# cslr_osd_001 register map
Vendor: Texas Instruments
Peripheral module from a debugger description file.
Registers are 32-bit, access per field, reset 0x0 unless marked. A register's access mark holds for its fields unless they carry their own. Offsets are as the file gives them; lines under a group give offsets from that group; [hi:lo] are bit positions; {n}, {i} and the like mark numbered series; 'fields as' and 'values as' point back to an identical list; <NAME> marks a mode.

## OSD — VPBE On Screen Display Subsystem (spec version: 1.00.w.02a)
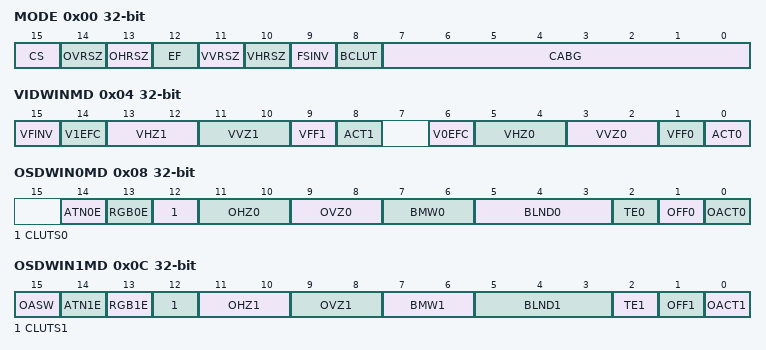
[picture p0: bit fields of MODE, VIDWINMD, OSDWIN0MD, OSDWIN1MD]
0x00 MODE — OSD mode register
  [15] CS rw — Cb/Cr or Cr/Cb format This bit selects the order of the input data relative to the placement of the Cb and Cr components
    0=CB_CR; 1=CR_CB
  [14] OVRSZ rw — OSD Window Vertical Expansion Enable When enabled, the bitmap window images are stretched by a factor of 6/5 in the vertical direction. Results in proper vertical sizing to display a normal VGA (640x480) image on a PAL television (720x576); i.e., 480 x 6/5=576
    0=X1; 1=X6_5
  [13] OHRSZ rw — OSD Window Horizontal Expansion Enable When enabled, the bitmap window images are stretched by a factor of 9/8 in the horizontal direction. Results in proper horizontal sizing to display a normal VGA (640x480) image on a PAL / NTSC television (720);
    0=X1; 1=X9_8
  [12] EF rw — Expansion Filter Enable Valid when either VVRSZ or VHRSZ is on, or video window smoothing is set. Caution is required when using the filter since expansion filter memory can only correspond to 720 horizontal pixels. *This bit is latched by VD.
    0=OFF; 1=ON
  [11] VVRSZ rw — Video Window Vertical Expansion Enable When enabled, the video window images are stretched by a factor of 6/5 in the vertical direction. Results in proper vertical sizing to display a normal VGA (640x480) image on a PAL television (720x576); i.e., 480 x 6/5=576 *This bit is latched by VD.
    0=X1; 1=X6_5
  [10] VHRSZ rw — Video Window Horizontal Expansion Enable When enabled, the video window images are stretched by a factor of 9/8 in the horizontal direction. Results in proper horizontal sizing to display a normal VGA (640x480) image on an NTSC/PAL television (720x???); i.e., 640 x 9/8 = 720 *This bit is latched by VD.
    0=X1; 1=X9_8
  [9] FSINV rw — Field signal inversion *This bit is latched by VD.
    0=UNINVERTED; 1=INVERTED
  [8] BCLUT rw — Background CLUT selection Selects look-up table for background color display *This bit is latched by VD.
    0=ROM; 1=RAM
  [7:0] CABG rw — Background Color CLUT Specifies the image display background color by CLUT address. In parts that do not display the image, color specified by this register is displayed.
0x04 VIDWINMD access not given — Video Window Mode Setup
  [15] VFINV rw — Video Window 0/1 Expansion filter coefficient Inverse Note: When V1EFC or V0EFC is set, this bit is valid
    0=NORMAL; 1=INVERSED
  [14] V1EFC rw — Video Window 1 Expansion filter coefficient Note: When VVRSZ and EF are set to 1, this bit is valid
    0=SAME4BOTH (same coefficients for field-0 and field-1); 1=DIFFERENT (different coefficients for field-0 and field-1)
  [13:12] VHZ1 rw — Video Window 0 horizontal direction zoom *This bit is latched by VD.
    0=X1; 1=X2; 2=X4
  [11:10] VVZ1 rw — Video Window 0 vertical direction zoom *This bit is latched by VD.
    0=X1; 1=X2; 2=X4
  [9] VFF1 rw — Video Window 0 display mode In Field mode, only the number of lines in a field, as specified in VIDWIN1YL, will be read from display memory and the data is repeated for each field sent to the VENC module. In Frame mode, 2x the number of lines in a field, as specified in VIDWIN1YL, will be read from display memory, with the data being interleaved for each field sent to the VENC module. This provides full vertical resolution of 2x VIDWIN1YL. *This bit is latched by VD.
    0=FIELDMODE; 1=FRAMEMODE
  [8] ACT1 rw — Sets image display on/off Video Window 0 *This bit is latched by VD.
    0=OFF; 1=ON
  [6] V0EFC rw — Video window 0 Expansion filter coefficient Note: When VVRSZ and EF are set to 1, this bit is valid
    values as V1EFC
  [5:4] VHZ0 rw — Video Window 0 horizontal direction zoom *This bit is latched by VD.
    0=X1; 1=X2; 2=X4
  [3:2] VVZ0 rw — Video Window 0 vertical direction zoom *This bit is latched by VD.
    0=X1; 1=X2; 2=X4
  [1] VFF0 rw — Video Window 0 display mode In Field mode, only the number of lines in a field, as specified in VIDWIN0YL, will be read from display memory and the data is repeated for each field sent to the VENC module. In Frame mode, 2x the number of lines in a field, as specified in VIDWIN0YL, will be read from display memory, with the data being interleaved for each field sent to the VENC module. This provides full vertical resolution of 2x VIDWIN0YL. *This bit is latched by VD.
    0=FIELDMODE; 1=FRAMEMODE
  [0] ACT0 rw — Sets image display on/off Video Window 0 *This bit is latched by VD.
    0=OFF; 1=ON
0x08 OSDWIN0MD — OSD Window 0 Mode Setup
  [14] ATN0E rw — Attenuation Enable for REC601
    0=NORMAL (Normal levels (Y 0-255, Cr 0-255, Cb 0-255)); 1=ATTENUATED (Attenuated levels (Y 16-235, Cr 16-240, Cb 16-240))
  [13] RGB0E rw — RGB input for window 0 Enable Note: When RGB0E bit in OSDWIN0MD register is set/enabled, RGB1E should not be set to 1 (parallel use is not allowed). The following equation is used to calculate YcbCr when RGB0E is set to 1. Y = 0.2990*R + 0.5870*G + 0.1140*B Cb = -0.1687*R - 0.3313*G + 0.5000*B + Offset(128) Cr = 0.5000*R - 0.4187*G - 0.0813*B + Offset(128)
    0=BMPLUT_MODE (bitmap input); 1=RGB16_MODE (16-bit RGB mode)
  [12] CLUTS0 rw — CLUT select for OSD Window 0 Selects look-up table that is used for OSD Window0 *This bit is latched by VD.
    0=ROM_LUT (ROM-look-up table); 1=RAM_LUT (RAM-look-up table)
  [11:10] OHZ0 rw — OSD Window0 Horizontal Zoom *This bit is latched by VD.
    0=X1; 1=X2; 2=X4
  [9:8] OVZ0 rw — OSD Window0 Vertical Zoom *This bit is latched by VD.
    0=X1; 1=X2; 2=X4
  [7:6] BMW0 rw — Bitmap bit width for OSD window 0 *This bit is latched by VD. Note: This is valid only for bitmap type, and when the OSD window is in RGB input mode, bit width is automatically set to 16-bit and this register setting is ignored
    0=1_BIT; 1=2_BITS; 2=4_BITS; 3=8_BITS
  [5:3] BLND0 rw — Blending Ratio for OSD Window 0 Sets blending ratio of OSD Window 0 and Video Window 0 *This bit is latched by VD.
    0=OSD0_VID1 (W0-0 V0-1); 1=OSD1_VID7 (W0-1/8 V0-7/8); 2=OSD2_VID6 (W0-2/8 V0-6/8); 3=OSD3_VID5 (W0-3/8 V0-5/8); 4=OSD4_VID4 (W0-4/8 V0-4/8); 5=OSD5_VID3 (W0-5/8 V0-3/8); 6=OSD6_VID2 (W0-6/8 V0-2/8); 7=OSD1_VID0 (W0-1 V0-0)
  [2] TE0 rw — Transparency Enable for OSD Window 0 When Transparency is disabled, the entire bitmap window is blended with the video windows according to BLND0. Bitmap Mode When Transparency is enabled, blending is only performed for pixels whose bitmap value is 0, according to BLND0. RGB Mode When Transparency is enabled and the pixel value is the same as TRANSPVAL, the YCbCr data converted from RGB value and video windows are blended according to the blending ratio specified in BLND0. *This bit is latched by VD.
    0=DISABLE; 1=ENABLE
  [1] OFF0 rw — OSD Window 0 Display Mode In Field mode, only the number of lines in a field, as specified in OSDWIN0YL, will be read from display memory and the data is repeated for each field sent to the VENC module. In Frame mode, 2x the number of lines in a field, as specified in OSDWIN0YL, will be read from display memory, with the data being interleaved for each field sent to the VENC module. This provides full vertical resolution of 2x OSDWIN0YL. *This bit is latched by VD.
    0=FIELDMODE; 1=FRAMEMODE
  [0] OACT0 rw — OSD Window 0 Active (displayed) *This bit is latched by VD.
    0=OFF; 1=ON
0x0C OSDWIN1MD — OSD Window 1 Mode Setup
  [15] OASW rw — OSD Window 1 Attribute Mode Enable This bit enables attribute mode for OSD WindoW0. *This bit is latched by VD.
    0=OSDWINDOW1 (OSD WindoW0); 1=ATTRIBUTEWINDOW
  [14] ATN1E rw — Attenuation Enable for REC601 OASW=0
    values as OSDWIN0MD.ATN0E
  [13] RGB1E rw — RGB input for window 1 Enable OASW=0 Note: When RGB0E bit in OSDWIN1MD register is set/enabled, RGB0E should not be set to 1 (parallel use is not allowed). The following equation is used to calculate YcbCr when RGB1E is set to 1. Y = 0.2990*R + 0.5870*G + 0.1140*B Cb = -0.1687*R - 0.3313*G + 0.5000*B + Offset(128) Cr = 0.5000*R - 0.4187*G - 0.0813*B + Offset(128)
    0=BMPLUT_MODE (bitmap input); 1=RGB16_MODE (16-bit RGB mode)
  [12] CLUTS1 rw — CLUT Select for OSD Window 1 OASW=0 Selects look-up table that is used for OSD WindoW 0
    0=ROM_LUT (ROM-look-up table); 1=RAM_LUT (RAM-look-up table)
  [11:10] OHZ1 rw — OSD WindoW 1 Horizontal Zoom OASW=0 *This bit is latched by VD.
    0=X1; 1=X2; 2=X4
  [9:8] OVZ1 rw — OSD WindoW 1 Vertical Zoom OASW=0 *This bit is latched by VD.
    0=X1; 1=X2; 2=X4
  [7:6] BMW1 rw — Bitmap Bit Width for OSD Window 1 OASW=0 Bitmap bit width for OSD WindoW0 *This bit is latched by VD.
    0=1_BIT; 1=2_BITS; 2=4_BITS; 3=8_BITS
  [5:3] BLND1 rw — Blending Ratio for OSD WindoW 1 OASW=0 Sets blending ratio of OSD window 1 and Video Window 0 *This bit is latched by VD.
    values as OSDWIN0MD.BLND0
  [2] TE1 rw — Transparency Enable for OSD Window 1 OASW=0 When Transparency is disabled, the entire bitmap window is blended with the video windows according to BLND1. Bitmap Mode When Transparency is enabled, blending is only performed for pixels whose bitmap value is 0, according to BLND1. RGB Mode When Transparency is enabled and the pixel value is the same as TRANSPVAL, the YCbCr data converted from RGB value and video windows are blended according to the blending ratio specified in BLND1. *This bit is latched by VD.
    0=DISABLE; 1=ENABLE
  [1] OFF1 rw — OSD Window 1 Display Mode OASW=0 In Field mode, only the number of lines in a field, as specified in OSDWIN1YL, will be read from display memory and the data is repeated for each field sent to the VENC module. In Frame mode, 2x the number of lines in a field, as specified in OSDWIN1YL, will be read from display memory, with the data being interleaved for each field sent to the VENC module. This provides full vertical resolution of 2x OSDWIN1YL. *This bit is latched by VD.
    0=FIELDMODE; 1=FRAMEMODE
  [0] OACT1 rw — OSD Window 1 Active (displayed) OASW=0 *This bit is latched by VD.
    0=OFF; 1=ON
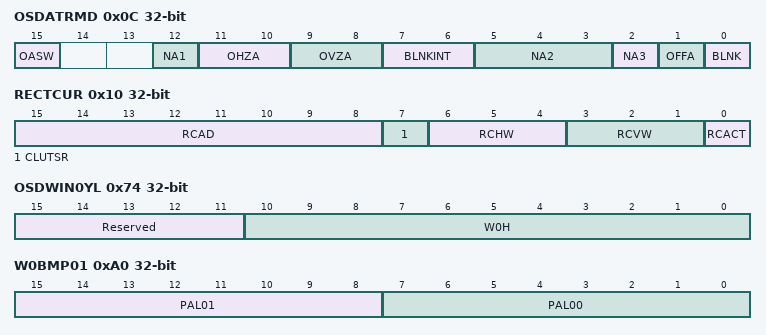
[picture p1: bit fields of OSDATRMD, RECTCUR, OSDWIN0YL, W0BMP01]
0x0C OSDATRMD access not given — OSD Attribute Window Mode Setup
  [15] OASW rw — OSD Window 1 Attribute Mode Enable This bit enables attribute mode for OSD WindoW0. *This bit is latched by VD.
    0=OSDWINDOW1 (OSD WindoW0); 1=ATTRIBUTEWINDOW
  [12] NA1 rw — Not Applicable in Attribute Window OASW=1 Not Used, Please set to 0 *This bit is latched by VD.
  [11:10] OHZA rw — OSD Attribute Window Horizontal Zoom OASW=1 *This bit is latched by VD.
    0=X1; 1=X2; 2=X4
  [9:8] OVZA rw — OSD WindoW0 or Attribute Window Vertical Zoom OASW=1 *This bit is latched by VD.
    0=X1; 1=X2; 2=X4
  [7:6] BLNKINT rw — Blinking Interval OASW=1 Specifies the blinking interval of the attribute window in units of 8 VD pulses *This bit is latched by VD.
    0=1_UNIT; 1=2_UNITS; 2=3_UNITS; 3=4_UNITS
  [5:3] NA2 rw — Not Applicable in Attribute Window OASW=1 Not Used, Please set to 0 *This bit is latched by VD.
  [2] NA3 rw — Not Applicable in Attribute Window OASW=1 Not Used, Please set to 0 *This bit is latched by VD.
  [1] OFFA rw — OSD Attribute Window Display Mode OASW=1 *This bit is latched by VD.
    0=FIELDMODE; 1=FRAMEMODE
  [0] BLNK rw — OSD Attribute Window Blink Enable OASW=1 *This bit is latched by VD.
    0=DISABLE; 1=ENABLE
0x10 RECTCUR — Rectangular Cursor Setup
  [15:8] RCAD rw — Rectangular Cursor Color Palette Address
  [7] CLUTSR rw — CLUT Select *This bit is latched by VD.
    0=ROM_LUT (ROM-look-up table); 1=RAM_LUT (RAM-look-up table)
  [6:4] RCHW rw — Rectangular Cursor Horizontal Line Width Width is 4xRCHW, with 0 interpreted as 1 pixel Range is: 1,4,8,16,20,24,28 pixels *This bit is latched by VD.
  [3:1] RCVW rw — Rectangular Cursor Vertical Line Width Width is 2xRCVW, with 0 interpreted as 1 line Range is: 1,2,4,6,8,10,12,14 lines *This bit is latched by VD.
  [0] RCACT rw — Rectangular Cursor Active (displayed) *This bit is latched by VD.
    0=OFF; 1=ON
0x14 RSV0 ro — Reserved
0x18 VIDWIN0OFST — Video Window 0 Offset
  [8:0] V0LO rw — Video Window 0 Line Offset Number of burst transfers (32-bytes) in a horizontal line. Video data format is YCbYCr, or 32-bits per 2 pixels, which gives 16-pixels/burst: Line width in pixels/16 e.g., 720/16 = 45 (0x2D) Note: If line width setting for the window result in a non-integer value, round the value up to the next larger integer and organize the data in SDRAM so that each line begins on a burst boundary. *This bit is latched by VD.
0x1C VIDWIN1OFST — Video Window 1 Offset
  [8:0] V1LO rw — Video Window 1 Line Offset Number of burst transfers (32-bytes) in a horizontal line. Video data format is YCbYCr, or 32-bits per 2 pixels, which gives 16-pixels/burst: Line width in pixels/16 e.g., 720/16 = 45 (0x2D) Note: If line width setting for the window result in a non-integer value, round the value up to the next larger integer and organize the data in SDRAM so that each line begins on a burst boundary. *This bit is latched by VD.
0x20 OSDWIN0OFST — OSD Window 0 Offset
  [8:0] O0LO rw — OSD Window 0 Line Offset Number of burst transfers (32-bytes) in a horizontal line. This depends on OSD window bit depth: Line width in pixels * bitdepth/256-bits/burst e.g., 64*8/256 = 2 Example: Offsets for 256 pixels horizontal: 1-bit mode : ((256x 1)/8)/32 = 1(0x0001) 2-bit mode : ((256x 2)/8)/32 = 2(0x0002) 4-bit mode : ((256x 4)/8)/32 = 4(0x0004) 8-bit mode : ((256x 8)/8)/32 = 8(0x0008) RGB565 mode : ((256x16)/8)/32 = 16(0x0010) Note: If line width and bitdepth settings for the window result in a non-integer value, round the value up to the next larger integer and organize the data in SDRAM so that each line begins on a burst boundary. *This bit is latched by VD.
0x24 OSDWIN1OFST — OSD Window 1 Offset
  [8:0] O1LO rw — OSD Window 1 Line Offset Number of burst transfers (32-bytes) in a horizontal line. This depends on OSD window bit depth: Line width in pixels * bitdepth/256-bits/burst e.g., 64*8/256 = 2 Example: Offsets for 256 pixels horizontal: 1-bit mode : ((256x 1)/8)/32 = 1(0x0001) 2-bit mode : ((256x 2)/8)/32 = 2(0x0002) 4-bit mode : ((256x 4)/8)/32 = 4(0x0004) 8-bit mode : ((256x 8)/8)/32 = 8(0x0008) RGB565 mode : ((256x16)/8)/32 = 16(0x0010) Note: If line width and bitdepth settings for the window result in a non-integer value, round the value up to the next larger integer and organize the data in SDRAM so that each line begins on a burst boundary. *This bit is latched by VD.
0x28 RSV1 ro — Reserved
0x2C VIDWIN0ADR ro — Video Window 0 Address
  [31:0] VIDWIN0ADR — Video Window 0 SDRAM Source Address The SDRAM source address is an absolute byte address. Note that the address should be aligned on a 32-byte (burst) boundary. As a result, the 5 LSB's are ignored and reading this register will always show the 5 LSB's as 0. *This bit is latched by VD.
0x30 VIDWIN1ADR ro — Video Window 1 Address
  [31:0] VIDWIN1ADR — Video Window 1 SDRAM Source Address The SDRAM source address is an absolute byte address. Note that the address should be aligned on a 32-byte (burst) boundary. As a result, the 5 LSB's are ignored and reading this register will always show the 5 LSB's as 0. *This bit is latched by VD.
0x34 RSV2 ro — Reserved
0x38 OSDWIN0ADR ro — OSD Window 0 Address
  [31:0] OSDWIN0ADR — OSD Window 0 SDRAM Source Address The SDRAM source address is an absolute byte address. Note that the address should be aligned on a 32-byte (burst) boundary. As a result, the 5 LSB's are ignored and reading this register will always show the 5 LSB's as 0. *This bit is latched by VD.
0x3C OSDWIN1ADR ro — OSD Window 1 Address
  [31:0] OSDWIN1ADR — OSD Window 1 SDRAM Source Address The SDRAM source address is an absolute byte address. Note that the address should be aligned on a 32-byte (burst) boundary. As a result, the 5 LSB's are ignored and reading this register will always show the 5 LSB's as 0. *This bit is latched by VD.
0x40 BASEPX — Base Pixel X
  [9:0] BPX rw — Base Pixel in X Horizontal base display reference position for all windows. Specified as number of pixels from HD. Value is 24-512 *This bit is latched by VD.
0x44 BASEPY — Base Pixel Y
  [8:0] BPY rw — Base Pixel(Line) in Y vertical base display reference position for all windows. Specified as number of pixels(lines) from VD. Value used is MAX(BPY,1), i.e., minumum value is 1. *This bit is latched by VD.
0x48 VIDWIN0XP — Video Window 0 X-Position
  [9:0] V0X rw — Video Window 0 X-Position Horizontal display start position - number of pixels from display reference position (BASEPX) *This bit is latched by VD.
0x4C VIDWIN0YP — Video Window 0 Y-Position
  [8:0] V0Y rw — Video Window 0 Y-Position Vertical display start position - number of pixels/lines from display reference position (BASEPY) *This bit is latched by VD.
0x50 VIDWIN0XL — Video Window 0 X-Size
  [11:0] V0W rw — Video Window 0 X-Width Horizontal display width in pixels *This bit is latched by VD.
0x54 VIDWIN0YL — Video Window 0 Y-Size
  [10:0] V0H rw — Video Window 0 Y-Height Vertical display height in pixels/lines NOTE: In frame mode, specify in terms of lines/field. *This bit is latched by VD.
0x58 VIDWIN1XP — Video Window 1 X-Position
  [9:0] V1X rw — Video Window 1 X-Position Horizontal display start position - number of pixels from display reference position (BASEPX) *This bit is latched by VD.
0x5C VIDWIN1YP — Video Window 1 Y-Position
  [8:0] V1Y rw — Video Window 1 Y-Position Vertical display start position - number of pixels/lines from display reference position (BASEPY) *This bit is latched by VD.
0x60 VIDWIN1XL — Video Window 1 X-Size
  [11:0] V1W rw — Video Window 1 X-Width Horizontal display width in pixels *This bit is latched by VD.
0x64 VIDWIN1YL — Video Window 1 Y-Size
  [10:0] V1H rw — Video Window 1 Y-Height Vertical display height in pixels/lines NOTE: In frame mode, specify in terms of lines/field. *This bit is latched by VD.
0x68 OSDWIN0XP — OSD Bitmap Window 0 X-Position
  [9:0] W0X rw — OSD Window 0 X-Position Horizontal display start position - number of pixels from display reference position (BASEPX) *This bit is latched by VD.
0x6C OSDWIN0YP — OSD Bitmap Window 0 Y-Position
  [8:0] W0Y rw — OSD Window 0 Y-Position Vertical display start position - number of pixels/lines from display reference position (BASEPY) *This bit is latched by VD.
0x70 OSDWIN0XL — OSD Bitmap Window 0 X-Size
  [11:0] W0W rw — OSD Window 0 X-Width Horizontal display width in pixels *This bit is latched by VD.
0x74 OSDWIN0YL access not given (reset mask 0xFFFF07FF) — OSD Bitmap Window 0 Y-Size
  [15:11] Reserved — (access N)
  [10:0] W0H rw — OSD Window 0 Y-Height Vertical display height in pixels/lines NOTE: In frame mode, specify in terms of lines/field. *This bit is latched by VD.
0x78 OSDWIN1XP — OSD Bitmap Window 1 X-Position
  [9:0] W1X rw — OSD Window 1 X-Position Horizontal display start position - number of pixels from display reference position (BASEPX) *This bit is latched by VD.
0x7C OSDWIN1YP — OSD Bitmap Window 1 Y-Position
  [8:0] W1Y rw — OSD Window 1 Y-Position Vertical display start position - number of pixels/lines from display reference position (BASEPY) *This bit is latched by VD.
0x80 OSDWIN1XL — OSD Bitmap Window 1 X-Size
  [11:0] W1W rw — OSD Window 1 X-Width Horizontal display width in pixels *This bit is latched by VD.
0x84 OSDWIN1YL — OSD Bitmap Window 1 Y-Size
  [10:0] W1H rw — OSD Window 1 Y-Height Vertical display height in pixels/lines NOTE: In frame mode, specify in terms of lines/field. *This bit is latched by VD.
0x88 CURXP — Rectangular Cursor Window X-Position
  [9:0] RCSX rw — Rectangular Cursor Window X-Position Horizontal display start position - number of pixels from display reference position (BASEPX) *This bit is latched by VD.
0x8C CURYP — Rectangular Cursor Window Y-Position
  [8:0] RCSY rw — Rectangular Cursor Window Y-Position Vertical display start position - number of pixels from display reference position (BASEPY) *This bit is latched by VD.
0x90 CURXL — Rectangular Cursor Window X-Size
  [11:0] RCSW rw — Rectangular Cursor Window X-Width Horizontal display width in pixels *This bit is latched by VD.
0x94 CURYL — Rectangular Cursor Window Y-Size
  [10:0] RCSH rw — Rectangular Cursor Window Y-Height Vertical display height in pixels/lines NOTE: In frame mode, specify in terms of lines/field. *This bit is latched by VD.
0x98 RSV3 ro — Reserved
0x9C RSV4 ro — Reserved
0xA0 W0BMP01 — Window 0 Bitmap Value to Palette Map 0/1
  [15:8] PAL01 rw — Palette Address for Bitmap Value [1,x,x] - OSD Window 0 [4-bit, 2-bit, 1-bit]
  [7:0] PAL00 rw — Palette Address for Bitmap Value [0,0,0] - OSD Window 0 [4-bit, 2-bit, 1-bit]
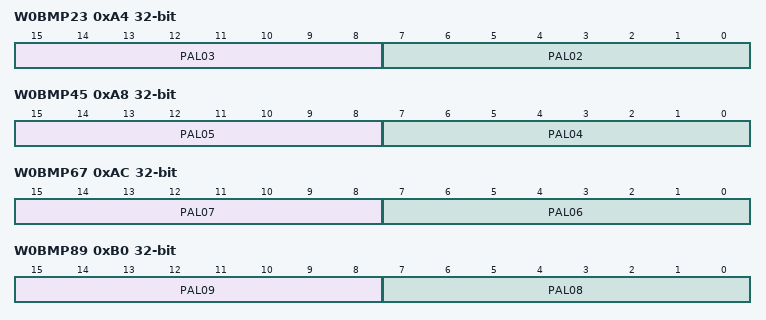
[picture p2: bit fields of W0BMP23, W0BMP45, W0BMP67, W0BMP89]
0xA4 W0BMP23 — Window 0 Bitmap Value to Palette Map 2/3
  [15:8] PAL03 rw — Palette Address for Bitmap Value [3,x,x] - OSD Window 0 [4-bit, 2-bit, 1-bit]
  [7:0] PAL02 rw — Palette Address for Bitmap Value [2,x,x] - OSD Window 0 [4-bit, 2-bit, 1-bit]
0xA8 W0BMP45 — Window 0 Bitmap Value to Palette Map 4/5
  [15:8] PAL05 rw — Palette Address for Bitmap Value [5,1,x] - OSD Window 0 [4-bit, 2-bit, 1-bit]
  [7:0] PAL04 rw — Palette Address for Bitmap Value [4,x,x] - OSD Window 0 [4-bit, 2-bit, 1-bit]
0xAC W0BMP67 — Window 0 Bitmap Value to Palette Map 6/7
  [15:8] PAL07 rw — Palette Address for Bitmap Value [7,x,x] - OSD Window 0 [4-bit, 2-bit, 1-bit]
  [7:0] PAL06 rw — Palette Address for Bitmap Value [6,x,x] - OSD Window 0 [4-bit, 2-bit, 1-bit]
0xB0 W0BMP89 — Window 0 Bitmap Value to Palette Map 8/9
  [15:8] PAL09 rw — Palette Address for Bitmap Value [9,x,x] - OSD Window 0 [4-bit, 2-bit, 1-bit]
  [7:0] PAL08 rw — Palette Address for Bitmap Value [8,x,x] - OSD Window 0 [4-bit, 2-bit, 1-bit]
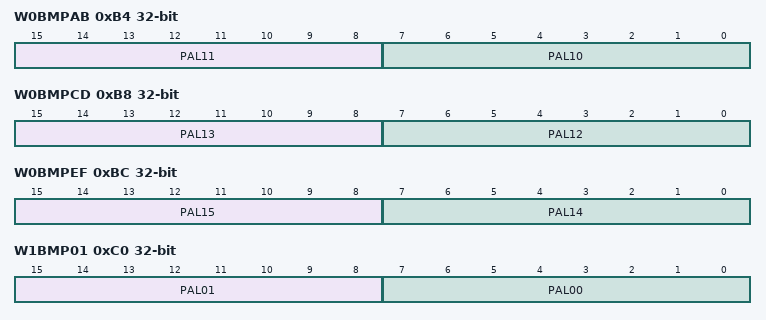
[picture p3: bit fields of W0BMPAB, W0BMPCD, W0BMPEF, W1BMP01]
0xB4 W0BMPAB — Window 0 Bitmap Value to Palette Map A/B
  [15:8] PAL11 rw — Palette Address for Bitmap Value [B,x,x] - OSD Window 0 [4-bit, 2-bit, 1-bit]
  [7:0] PAL10 rw — Palette Address for Bitmap Value [A,2,x] - OSD Window 0 [4-bit, 2-bit, 1-bit]
0xB8 W0BMPCD — Window 0 Bitmap Value to Palette Map C/D
  [15:8] PAL13 rw — Palette Address for Bitmap Value [D,x,x] - OSD Window 0 [4-bit, 2-bit, 1-bit]
  [7:0] PAL12 rw — Palette Address for Bitmap Value [C,x,x] - OSD Window 0 [4-bit, 2-bit, 1-bit]
0xBC W0BMPEF — Window 0 Bitmap Value to Palette Map E/F
  [15:8] PAL15 rw — Palette Address for Bitmap Value [F,3,1] - OSD Window 0 [4-bit, 2-bit, 1-bit]
  [7:0] PAL14 rw — Palette Address for Bitmap Value [E,x,x] - OSD Window 0 [4-bit, 2-bit, 1-bit]
0xC0 W1BMP01 — Window 1 Bitmap Value to Palette Map 0/1
  [15:8] PAL01 rw — Palette Address for Bitmap Value [1,x,x] - OSD Window 1 [4-bit, 2-bit, 1-bit]
  [7:0] PAL00 rw — Palette Address for Bitmap Value [0,0,0] - OSD Window 1 [4-bit, 2-bit, 1-bit]
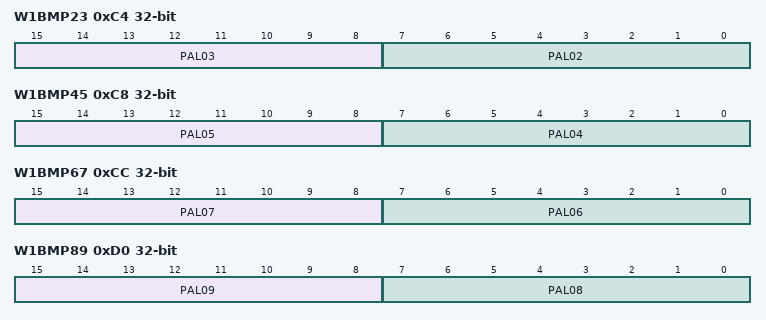
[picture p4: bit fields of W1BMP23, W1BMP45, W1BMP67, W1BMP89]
0xC4 W1BMP23 — Window 1 Bitmap Value to Palette Map 2/3
  [15:8] PAL03 rw — Palette Address for Bitmap Value [3,x,x] - OSD Window 1 [4-bit, 2-bit, 1-bit]
  [7:0] PAL02 rw — Palette Address for Bitmap Value [2,x,x] - OSD Window 1 [4-bit, 2-bit, 1-bit]
0xC8 W1BMP45 — Window 1 Bitmap Value to Palette Map 4/5
  [15:8] PAL05 rw — Palette Address for Bitmap Value [5,1,x] - OSD Window 1 [4-bit, 2-bit, 1-bit]
  [7:0] PAL04 rw — Palette Address for Bitmap Value [4,x,x] - OSD Window 1 [4-bit, 2-bit, 1-bit]
0xCC W1BMP67 — Window 1 Bitmap Value to Palette Map 6/7
  [15:8] PAL07 rw — Palette Address for Bitmap Value [7,x,x] - OSD Window 1 [4-bit, 2-bit, 1-bit]
  [7:0] PAL06 rw — Palette Address for Bitmap Value [6,x,x] - OSD Window 1 [4-bit, 2-bit, 1-bit]
0xD0 W1BMP89 — Window 1 Bitmap Value to Palette Map 8/9
  [15:8] PAL09 rw — Palette Address for Bitmap Value [9,x,x] - OSD Window 1 [4-bit, 2-bit, 1-bit]
  [7:0] PAL08 rw — Palette Address for Bitmap Value [8,x,x] - OSD Window 1 [4-bit, 2-bit, 1-bit]
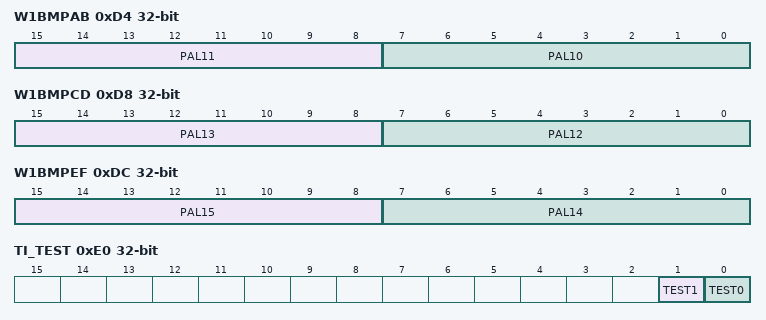
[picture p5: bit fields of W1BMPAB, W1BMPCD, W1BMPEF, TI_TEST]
0xD4 W1BMPAB — Window 1 Bitmap Value to Palette Map A/B
  [15:8] PAL11 rw — Palette Address for Bitmap Value [B,x,x] - OSD Window 1 [4-bit, 2-bit, 1-bit]
  [7:0] PAL10 rw — Palette Address for Bitmap Value [A,2,x] - OSD Window 1 [4-bit, 2-bit, 1-bit]
0xD8 W1BMPCD — Window 1 Bitmap Value to Palette Map C/D
  [15:8] PAL13 rw — Palette Address for Bitmap Value [D,x,x] - OSD Window 1 [4-bit, 2-bit, 1-bit]
  [7:0] PAL12 rw — Palette Address for Bitmap Value [C,x,x] - OSD Window 1 [4-bit, 2-bit, 1-bit]
0xDC W1BMPEF — Window 1 Bitmap Value to Palette Map E/F
  [15:8] PAL15 rw — Palette Address for Bitmap Value [F,3,1] - OSD Window 1 [4-bit, 2-bit, 1-bit]
  [7:0] PAL14 rw — Palette Address for Bitmap Value [E,x,x] - OSD Window 1 [4-bit, 2-bit, 1-bit]
0xE0 TI_TEST
  [1] TEST1 rw — TI Test #1
    0=NORMAL (Normal mode); 1=RESET_ALL_REGS (All registers are loaded with default values)
  [0] TEST0 rw — TI Test #0
    0=NORMAL (Normal mode); 1=TEST_MDODE (TI test mode)
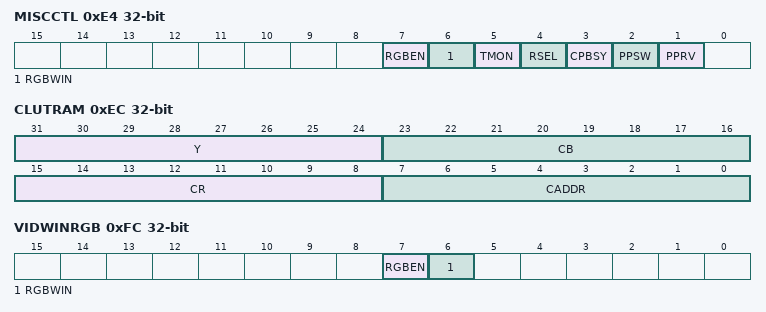
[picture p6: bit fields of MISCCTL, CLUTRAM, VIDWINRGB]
0xE4 MISCCTL access not given — Miscellaneous Control
  [7] RGBEN rw — Video Window RGB Mode Enable
    0=DISABLE; 1=ENABLE
  [6] RGBWIN rw — Video Window to use for RGB Mode
    0=VIDWIN0 (Video Window 0); 1=VIDWIN1 (Video Window 1)
  [5] TMON rw — TI Internal Test Set to 0
  [4] RSEL rw — CLUT ROM Selection
    0=CLUT0_DM270; 1=CLUT1_DM320
  [3] CPBSY ro — CLUT Write Busy Used when writing CLUT data to RAM.
    0=NOTBUSY (Not busy, okay to write); 1=BUSY (Busy, do not write)
  [2] PPSW rw — Ping-pong buffer toggle select When PPRV=0: 0: Use address in VIDWIN0ADR 1: Use address in PPVWIN0ADR When PPRV=1 0: Use address in PPVWIN0ADR 1: Use address in VIDWIN0ADR
    0=PPRV0_V0ADR_PPRV1_PPADR (PPRV=0 -> VIDWIN0ADR / PPRV=1 -> PPVWIN0ADR); 1=PPRV0_PPADR_PPRV1_V0ADR (PPRV=0 -> PPVWIN0ADR / PPRV=1 -> VIDWIN0ADR)
  [1] PPRV — Ping-pong buffer Reverse Inverts polarity of internal select signal. Affects PPSW
0xE8 RSV5 ro — Reserved
0xEC CLUTRAM rw — CLUT RAM Setup
  [31:24] Y — Write data (Y) into built-in CLUT-RAM
  [23:16] CB — Write data (Cb) into built-in CLUT-RAM
  [15:8] CR — Write data (Cr) into built-in CLUT-RAM
  [7:0] CADDR — CLUT Write Palette Address When updating CLUT-RAM: - verify CPBSY=0 in MISCCTL before writing to this register - any writes to this register will transfer the contents of Y, CB, and CR fields to CLUT RAM at address specified by CADDR
0xF0 TRANSPVAL — Reserved
  [15:0] RGBTRANS rw — OSD Window Transparency value for RGB565 input mode When OSD window is set to RGB565 input mode and Transparency is enabled, this value determines the RGB value of the transparent color.
0xF4 RSV6 ro — Reserved
0xF8 PPVWIN0ADR rw — Ping-Pong Video Window 0 Address
  [31:0] PPVWIN0ADR — Ping-pong Video Window 0 Address The SDRAM source address is an absolute byte address. Note that the address should be aligned on a 32-byte (burst) boundary. As a result, the 5 LSB's are ignored and reading this register will always show the 5 LSB's as 0. *This bit is latched by VD.
0xFC VIDWINRGB — Video Window RGB Control
  [7] RGBEN rw — Video Window RGB Mode Enable
    0=DISABLE; 1=ENABLE
  [6] RGBWIN rw — Video Window to use for RGB Mode
    0=VIDWIN0 (Video Window 0); 1=VIDWIN1 (Video Window 1)
